# GD32VW553x register map
Vendor: GigaDevice; File version: 1.0
CPU: OTHER r0p0, little endian, no MPU, no FPU, 4 interrupt priority bits
Registers are 32-bit, read-write, reset 0x0 unless marked. A register's access mark holds for its fields unless they carry their own. Offsets are from the block's base; [hi:lo] are bit positions.

## PMU — Power management unit
Base 0x40007000
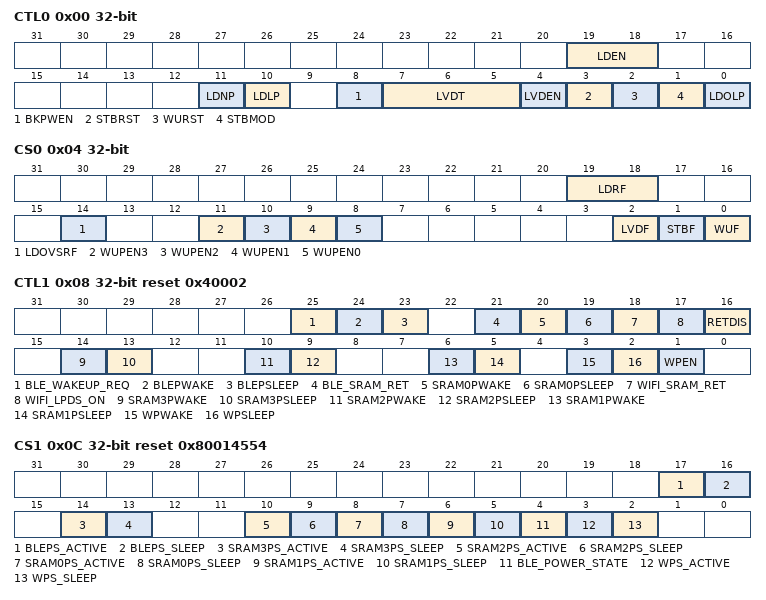
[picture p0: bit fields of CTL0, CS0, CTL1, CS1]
0x00 CTL0 — Control register 0
  [19:18] LDEN — Low-driver mode enable in Deep-sleep mode
  [11] LDNP — Low-driver mode when use normal power LDO
  [10] LDLP — Low-driver mode when use low power LDO
  [8] BKPWEN — Backup Domain write enable
  [7:5] LVDT — Low Voltage Detector Threshold
  [4] LVDEN — Low Voltage Detector Enable
  [3] STBRST — Standby Flag Reset
  [2] WURST — Wakeup Flag Reset
  [1] STBMOD — Standby Mode
  [0] LDOLP — LDO Low Power Mode
0x04 CS0 — Control and status register 0
  [19:18] LDRF — Low-driver mode ready flag
  [14] LDOVSRF ro — LDO voltage select ready flag
  [11] WUPEN3 — WKUP Pin3 (PA12) Enable
  [10] WUPEN2 — WKUP Pin2 (PB2) Enable
  [9] WUPEN1 — WKUP Pin1 (PA15) Enable
  [8] WUPEN0 — WKUP Pin0 (PA2) Enable
  [2] LVDF ro — Low Voltage Detector Status Flag
  [1] STBF ro — Standby Flag
  [0] WUF ro — Wakeup Flag
0x08 CTL1 reset 0x40002 — Control register 1
  [25] BLE_WAKEUP_REQ — BLE wakeup request
  [24] BLEPWAKE — wakeup BLE
  [23] BLEPSLEEP — BLE go to sleep
  [21] BLE_SRAM_RET — BLE sram enter retention mode when deepsleep and BLE sleep
  [20] SRAM0PWAKE — wakeup SRAM0
  [19] SRAM0PSLEEP — SRAM0 go to sleep
  [18] WIFI_SRAM_RET — WIFI sram enter retention mode when deepsleep and WIFI sleep
  [17] WIFI_LPDS_ON — WIFI auto lpds flow on
  [16] RETDIS — No retention register when WIFI power-off
  [14] SRAM3PWAKE — wakeup SRAM3
  [13] SRAM3PSLEEP — SRAM3 go to sleep
  [10] SRAM2PWAKE — wakeup SRAM2
  [9] SRAM2PSLEEP — SRAM2 go to sleep
  [6] SRAM1PWAKE — wakeup SRAM1
  [5] SRAM1PSLEEP — SRAM1 go to sleep
  [3] WPWAKE — WIFI wakeup
  [2] WPSLEEP — WIFI go to sleep
  [1] WPEN — enable WIFI power
0x0C CS1 reset 0x80014554 — Control and status register 1
  [17] BLEPS_ACTIVE ro — BLE is in active state
  [16] BLEPS_SLEEP ro — BLE is in sleep state
  [14] SRAM3PS_ACTIVE ro — SRAM3 is in active state
  [13] SRAM3PS_SLEEP ro — SRAM3 is in sleep state
  [10] SRAM2PS_ACTIVE ro — SRAM2 is in active state
  [9] SRAM2PS_SLEEP ro — SRAM2 is in sleep state
  [8] SRAM0PS_ACTIVE ro — SRAM0 is in active state
  [7] SRAM0PS_SLEEP ro — SRAM0 is in sleep state
  [6] SRAM1PS_ACTIVE ro — SRAM1 is in active state
  [5] SRAM1PS_SLEEP ro — SRAM1 is in sleep state
  [4] BLE_POWER_STATE ro — BLE power status
  [3] WPS_ACTIVE ro — WIFI is in active state
  [2] WPS_SLEEP ro — WIFI is in sleep state
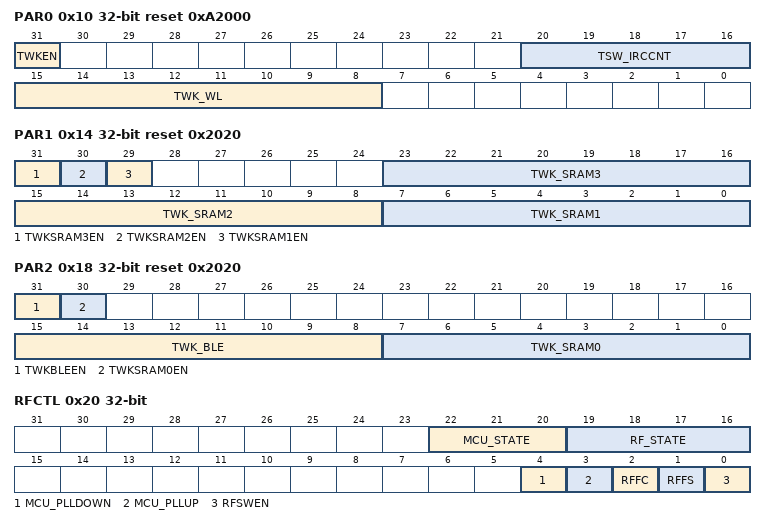
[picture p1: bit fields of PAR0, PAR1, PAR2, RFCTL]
0x10 PAR0 reset 0xA2000 — Parameter register 0
  [31] TWKEN — Wakeup time of WIFI_OFF domain
  [20:16] TSW_IRCCNT — When enter deep-sleep, switch to IRC16M clock. Wait the IRC16M COUNTER
  [15:8] TWK_WL — Use software value when wake up WIFI_OFF or not
0x14 PAR1 reset 0x2020 — Parameter register 1
  [31] TWKSRAM3EN — Use software value when wake up SRAM3 or not
  [30] TWKSRAM2EN — Use software value when wake up SRAM2 or not
  [29] TWKSRAM1EN — Use software value when wake up SRAM1 or not
  [23:16] TWK_SRAM3 — Wakeup time of SRAM3 domain
  [15:8] TWK_SRAM2 — Wakeup time of SRAM2 domain
  [7:0] TWK_SRAM1 — Wakeup time of SRAM1 domain
0x18 PAR2 reset 0x2020 — Parameter register 2
  [31] TWKBLEEN — Use software value when wake up BLE or not
  [30] TWKSRAM0EN — Use software value when wake up SRAM0 or not
  [15:8] TWK_BLE — Wakeup time of BLE domain
  [7:0] TWK_SRAM0 — Wakeup time of SRAM0 domain
0x20 RFCTL — RF Control register
  [22:20] MCU_STATE ro — MCU status
  [19:16] RF_STATE ro — RF status
  [4] MCU_PLLDOWN — Software force close, close MCU PLL power
  [3] MCU_PLLUP — Software force open, open MCU PLL power
  [2] RFFC — Software set or clear (must > 2 IRC16M clock)
  [1] RFFS — Software set or clear (must > 2 IRC16M clock)
  [0] RFSWEN — RF sequence configured by software or hardware
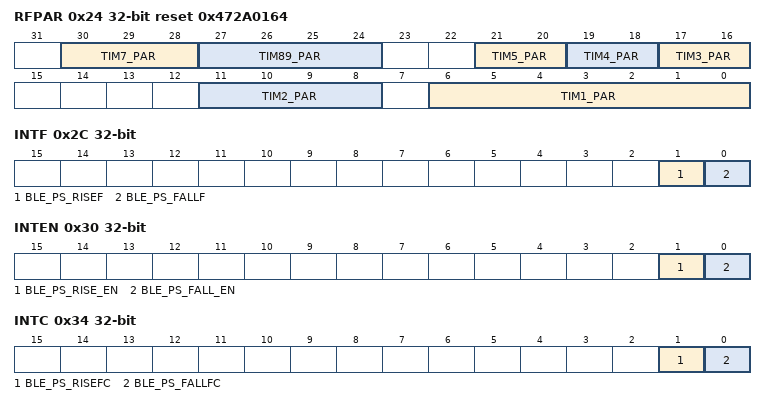
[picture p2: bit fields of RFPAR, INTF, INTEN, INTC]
0x24 RFPAR reset 0x472A0164 — RF timer parameter register
  [30:28] TIM7_PAR — RF timer parameter 7
  [27:24] TIM89_PAR — RF timer parameter 89
  [21:20] TIM5_PAR — RF timer parameter 5
  [19:18] TIM4_PAR — RF timer parameter 4
  [17:16] TIM3_PAR — RF timer parameter 3
  [11:8] TIM2_PAR — RF timer parameter 2
  [6:0] TIM1_PAR — RF timer parameter 1
0x2C INTF — PMU interrupt flag register
  [1] BLE_PS_RISEF ro — BLE power status rising edge interrupt flag
  [0] BLE_PS_FALLF ro — BLE power status falling edge interrupt flag
0x30 INTEN — PMU interrupt enable register
  [1] BLE_PS_RISE_EN — BLE power status rising edge interrupt enable
  [0] BLE_PS_FALL_EN — BLE power status falling edge interrupt enable
0x34 INTC — PMU interrupt clear register
  [1] BLE_PS_RISEFC — clear BLE power status rising edge interrupt flag
  [0] BLE_PS_FALLFC — clear BLE power status falling edge interrupt flag
